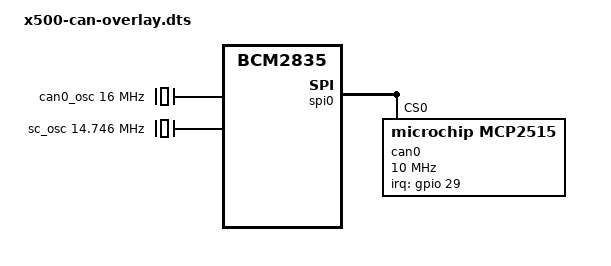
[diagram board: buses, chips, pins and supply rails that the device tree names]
/dts-v1/;
/plugin/;

/ {
 compatible = "brcm,bcm2835";

  /* disable spi-dev for spi0.0 */
  fragment@0 {
      target = <&spi0>;
      __overlay__ {
          status = "okay";
      };
  };

  fragment@1 {
    target = <&spidev0>;
    __overlay__ {
      status = "disabled";
    };
  };

  /* the interrupt pin of the can-controller */
  fragment@2 {
      target = <&gpio>;
      __overlay__ {
          can0_pins: can0_pins {
              brcm,pins = <29>;
              brcm,function = <0>; /* input */
          };
      };
  };

  /* the clock/oscillator of the can-controller */
  fragment@3 {
      target-path = "/clocks";
      __overlay__ {
          /* external oscillator of mcp2515 on SPI0.0 */
          can0_osc: can0_osc {
              compatible = "fixed-clock";
              #clock-cells = <0>;
              clock-frequency  = <16000000>;
          };
          /* external oscillator of sc16is740 on I2C0 */
          sc_osc: sc_osc {
            compatible = "fixed-clock";
            #clock-cells = <1>;
            clock-frequency  = <14745600>;
            clock-output-names = "sc_osc";
          };
      };
  };

  /* the spi config of the can-controller itself binding everything together */
  fragment@4 {
      target = <&spi0>;
      __overlay__ {
          /* needed to avoid dtc warning */
          #address-cells = <1>;
          #size-cells = <0>;
          cs-gpios = <0>, <0>;
          status = "okay";
          can0: mcp2515@0 {
              reg = <0>;
              compatible = "microchip,mcp2515";
              pinctrl-names = "default";
              pinctrl-0 = <&can0_pins>;
              spi-max-frequency = <10000000>;
              interrupt-parent = <&gpio>;
              interrupts = <29 8>; /* IRQ_TYPE_LEVEL_LOW */
              clocks = <&can0_osc>;
          };
      };
  };

  fragment@5 {
    target = <&spi0_cs_pins>;
    __overlay__ {
      brcm,pins = <8 7>;
      brcm,function = <4>; /* alt0 */
   };
  };
};
